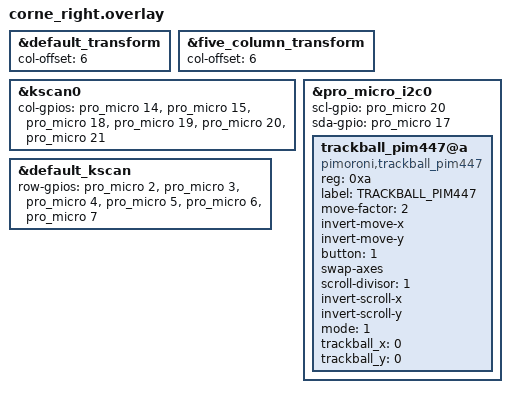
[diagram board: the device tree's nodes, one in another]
/*
 * Copyright (c) 2020 Pete Johanson
 *
 * SPDX-License-Identifier: MIT
 */

#include "corne.dtsi"

&default_transform {
    col-offset = <6>;
};

&five_column_transform {
    col-offset = <6>;
};

&kscan0 {
    col-gpios
        = <&pro_micro 14 GPIO_ACTIVE_HIGH>
        , <&pro_micro 15 GPIO_ACTIVE_HIGH>
        , <&pro_micro 18 GPIO_ACTIVE_HIGH>
        , <&pro_micro 19 GPIO_ACTIVE_HIGH>
        , <&pro_micro 20 GPIO_ACTIVE_HIGH>
        , <&pro_micro 21 GPIO_ACTIVE_HIGH>
        ;
};

&pro_micro_i2c0 {
    status = "okay";
    
    // I2C 설정
    scl-gpio = <&pro_micro 20>; // SCL 핀을 GPIO 20으로 설정
    sda-gpio = <&pro_micro 17>; // SDA 핀을 GPIO 17으로 설정

    trackball_pim447@a {
        compatible = "pimoroni,trackball_pim447";
        reg = <0xa>;
        label = "TRACKBALL_PIM447";
        move-factor = <2>;      // Increase pointer velocity (default: 1)
        invert-move-x;          // Invert pointer X axis (left is right, and vice versa)
        invert-move-y;          // Invert pointer Y axis (up is down, and vice versa)
        button = <1>;           // Send right-click when pressing the ball (default: 0, ie. left-click)
        swap-axes;              // Swap X and Y axes (horizontal is vertical, and vice versa)
        scroll-divisor = <1>;   // Increase wheel velocity (default: 2)
        invert-scroll-x;        // Invert wheel X axis (left is right, and vice versa)
        invert-scroll-y;        // Invert wheel Y axis (up is down, and vice versa)
        mode = <1>;             // Act as mouse wheels at startup (default: PIM447_MOVE for a pointer)
        
        // trackball_x 및 trackball_y 노드 정의
        trackball_x = <0>; // 실제로는 이 값을 해당 핀이나 센서에 맞춰 정의해야 합니다.
        trackball_y = <0>; // 실제로는 이 값을 해당 핀이나 센서에 맞춰 정의해야 합니다.
    };
};

    &default_kscan {
    row-gpios = <&pro_micro 2 GPIO_ACTIVE_HIGH>
              , <&pro_micro 3 GPIO_ACTIVE_HIGH>
              , <&pro_micro 4 GPIO_ACTIVE_HIGH>
              , <&pro_micro 5 GPIO_ACTIVE_HIGH>
              , <&pro_micro 6 GPIO_ACTIVE_HIGH>
              , <&pro_micro 7 GPIO_ACTIVE_HIGH>;
};

